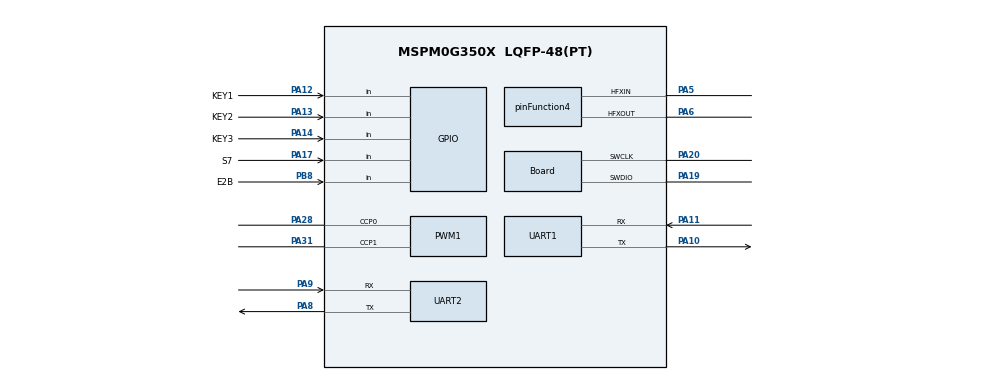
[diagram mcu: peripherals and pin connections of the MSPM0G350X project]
/**
 * @cliArgs --device "MSPM0G350X" --part "Default" --package "LQFP-48(PT)" --product "mspm0_sdk@2.05.01.01"
 * @versions {"tool":"1.24.0+4110"}
 */

/**
 * Import the modules used in this configuration.
 */
const GPIO    = scripting.addModule("/ti/driverlib/GPIO", {}, false);
const GPIO1   = GPIO.addInstance();
const GPIO2   = GPIO.addInstance();
const GPIO3   = GPIO.addInstance();
const GPIO4   = GPIO.addInstance();
const GPIO5   = GPIO.addInstance();
const GPIO6   = GPIO.addInstance();
const PWM     = scripting.addModule("/ti/driverlib/PWM", {}, false);
const PWM1    = PWM.addInstance();
const SYSCTL  = scripting.addModule("/ti/driverlib/SYSCTL");
const SYSTICK = scripting.addModule("/ti/driverlib/SYSTICK");
const TIMER   = scripting.addModule("/ti/driverlib/TIMER", {}, false);
const TIMER1  = TIMER.addInstance();
const TIMER2  = TIMER.addInstance();
const UART    = scripting.addModule("/ti/driverlib/UART", {}, false);
const UART1   = UART.addInstance();
const UART2   = UART.addInstance();

/**
 * Write custom configuration values to the imported modules.
 */
const divider5       = system.clockTree["PLL_CLK1_DIV"];
divider5.divideValue = 4;

const divider6       = system.clockTree["PLL_CLK2X_DIV"];
divider6.divideValue = 4;

const divider9       = system.clockTree["UDIV"];
divider9.divideValue = 2;

const gate7  = system.clockTree["MFCLKGATE"];
gate7.enable = true;

const multiplier2         = system.clockTree["PLL_QDIV"];
multiplier2.multiplyValue = 4;

const mux4       = system.clockTree["EXHFMUX"];
mux4.inputSelect = "EXHFMUX_XTAL";

const mux8       = system.clockTree["HSCLKMUX"];
mux8.inputSelect = "HSCLKMUX_SYSPLL2X";

const mux12       = system.clockTree["SYSPLLMUX"];
mux12.inputSelect = "zSYSPLLMUX_HFCLK";

const pinFunction4                        = system.clockTree["HFXT"];
pinFunction4.inputFreq                    = 40;
pinFunction4.enable                       = true;
pinFunction4.HFXTStartup                  = 10;
pinFunction4.HFCLKMonitor                 = true;
pinFunction4.peripheral.$assign           = "SYSCTL";
pinFunction4.peripheral.hfxInPin.$assign  = "PA5";
pinFunction4.peripheral.hfxOutPin.$assign = "PA6";

GPIO1.port                                  = "PORTA";
GPIO1.$name                                 = "LED";
GPIO1.associatedPins[0].assignedPortSegment = "Lower";
GPIO1.associatedPins[0].assignedPin         = "7";
GPIO1.associatedPins[0].$name               = "LED1";
GPIO1.associatedPins[0].initialValue        = "SET";

const Board                       = scripting.addModule("/ti/driverlib/Board", {}, false);
Board.peripheral.$assign          = "DEBUGSS";
Board.peripheral.swclkPin.$assign = "PA20";
Board.peripheral.swdioPin.$assign = "PA19";

GPIO2.$name                              = "KEY";
GPIO2.associatedPins.create(4);
GPIO2.associatedPins[0].direction        = "INPUT";
GPIO2.associatedPins[0].assignedPort     = "PORTA";
GPIO2.associatedPins[0].interruptEn      = true;
GPIO2.associatedPins[0].polarity         = "RISE";
GPIO2.associatedPins[0].$name            = "KEY1";
GPIO2.associatedPins[0].assignedPin      = "12";
GPIO2.associatedPins[0].internalResistor = "PULL_DOWN";
GPIO2.associatedPins[0].inputFilter      = "8_CYCLES";
GPIO2.associatedPins[0].pin.$assign      = "PA12";
GPIO2.associatedPins[1].$name            = "KEY2";
GPIO2.associatedPins[1].direction        = "INPUT";
GPIO2.associatedPins[1].assignedPort     = "PORTA";
GPIO2.associatedPins[1].assignedPin      = "13";
GPIO2.associatedPins[1].internalResistor = "PULL_DOWN";
GPIO2.associatedPins[1].inputFilter      = "3_CYCLES";
GPIO2.associatedPins[1].pin.$assign      = "PA13";
GPIO2.associatedPins[2].$name            = "KEY3";
GPIO2.associatedPins[2].direction        = "INPUT";
GPIO2.associatedPins[2].assignedPort     = "PORTA";
GPIO2.associatedPins[2].assignedPin      = "14";
GPIO2.associatedPins[2].internalResistor = "PULL_DOWN";
GPIO2.associatedPins[2].inputFilter      = "3_CYCLES";
GPIO2.associatedPins[2].pin.$assign      = "PA14";
GPIO2.associatedPins[3].$name            = "KEY4";
GPIO2.associatedPins[3].direction        = "INPUT";
GPIO2.associatedPins[3].assignedPort     = "PORTA";
GPIO2.associatedPins[3].assignedPin      = "15";
GPIO2.associatedPins[3].internalResistor = "PULL_DOWN";
GPIO2.associatedPins[3].inputFilter      = "3_CYCLES";

GPIO3.$name                               = "ENCODER";
GPIO3.associatedPins.create(4);
GPIO3.associatedPins[0].$name             = "E1A";
GPIO3.associatedPins[0].direction         = "INPUT";
GPIO3.associatedPins[0].assignedPort      = "PORTB";
GPIO3.associatedPins[0].assignedPin       = "18";
GPIO3.associatedPins[0].interruptEn       = true;
GPIO3.associatedPins[0].interruptPriority = "0";
GPIO3.associatedPins[0].polarity          = "RISE";
GPIO3.associatedPins[1].$name             = "E1B";
GPIO3.associatedPins[1].direction         = "INPUT";
GPIO3.associatedPins[1].assignedPort      = "PORTB";
GPIO3.associatedPins[1].assignedPin       = "6";
GPIO3.associatedPins[1].interruptEn       = true;
GPIO3.associatedPins[1].interruptPriority = "0";
GPIO3.associatedPins[1].polarity          = "RISE";
GPIO3.associatedPins[2].$name             = "E2A";
GPIO3.associatedPins[2].direction         = "INPUT";
GPIO3.associatedPins[2].assignedPort      = "PORTB";
GPIO3.associatedPins[2].assignedPin       = "7";
GPIO3.associatedPins[2].interruptEn       = true;
GPIO3.associatedPins[2].interruptPriority = "0";
GPIO3.associatedPins[2].polarity          = "RISE";
GPIO3.associatedPins[3].$name             = "E2B";
GPIO3.associatedPins[3].direction         = "INPUT";
GPIO3.associatedPins[3].assignedPort      = "PORTB";
GPIO3.associatedPins[3].assignedPin       = "8";
GPIO3.associatedPins[3].interruptEn       = true;
GPIO3.associatedPins[3].interruptPriority = "0";
GPIO3.associatedPins[3].polarity          = "RISE";
GPIO3.associatedPins[3].pin.$assign       = "PB8";

GPIO4.$name                          = "MOTOR";
GPIO4.associatedPins.create(4);
GPIO4.associatedPins[0].$name        = "AIN1";
GPIO4.associatedPins[0].assignedPort = "PORTA";
GPIO4.associatedPins[0].assignedPin  = "02";
GPIO4.associatedPins[1].$name        = "AIN2";
GPIO4.associatedPins[1].assignedPort = "PORTB";
GPIO4.associatedPins[1].assignedPin  = "24";
GPIO4.associatedPins[2].$name        = "BIN1";
GPIO4.associatedPins[2].assignedPort = "PORTB";
GPIO4.associatedPins[2].assignedPin  = "20";
GPIO4.associatedPins[3].$name        = "BIN2";
GPIO4.associatedPins[3].assignedPort = "PORTB";
GPIO4.associatedPins[3].assignedPin  = "19";

GPIO5.$name                          = "IIC";
GPIO5.associatedPins.create(2);
GPIO5.associatedPins[0].assignedPort = "PORTA";
GPIO5.associatedPins[0].assignedPin  = "0";
GPIO5.associatedPins[0].$name        = "SCL";
GPIO5.associatedPins[0].initialValue = "SET";
GPIO5.associatedPins[0].ioStructure  = "OD";
GPIO5.associatedPins[1].$name        = "SDA";
GPIO5.associatedPins[1].assignedPort = "PORTA";
GPIO5.associatedPins[1].assignedPin  = "1";
GPIO5.associatedPins[1].initialValue = "SET";
GPIO5.associatedPins[1].ioStructure  = "OD";

GPIO6.$name                          = "TRACK";
GPIO6.associatedPins.create(8);
GPIO6.associatedPins[0].$name        = "S1";
GPIO6.associatedPins[0].direction    = "INPUT";
GPIO6.associatedPins[0].assignedPort = "PORTA";
GPIO6.associatedPins[0].assignedPin  = "25";
GPIO6.associatedPins[1].$name        = "S2";
GPIO6.associatedPins[1].direction    = "INPUT";
GPIO6.associatedPins[1].assignedPort = "PORTA";
GPIO6.associatedPins[1].assignedPin  = "24";
GPIO6.associatedPins[2].$name        = "S3";
GPIO6.associatedPins[2].direction    = "INPUT";
GPIO6.associatedPins[2].assignedPort = "PORTA";
GPIO6.associatedPins[2].assignedPin  = "23";
GPIO6.associatedPins[3].$name        = "S4";
GPIO6.associatedPins[3].direction    = "INPUT";
GPIO6.associatedPins[3].assignedPort = "PORTA";
GPIO6.associatedPins[3].assignedPin  = "22";
GPIO6.associatedPins[4].direction    = "INPUT";
GPIO6.associatedPins[4].$name        = "S5";
GPIO6.associatedPins[4].assignedPort = "PORTA";
GPIO6.associatedPins[4].assignedPin  = "21";
GPIO6.associatedPins[5].$name        = "S6";
GPIO6.associatedPins[5].direction    = "INPUT";
GPIO6.associatedPins[5].assignedPort = "PORTB";
GPIO6.associatedPins[5].assignedPin  = "9";
GPIO6.associatedPins[6].$name        = "S7";
GPIO6.associatedPins[6].direction    = "INPUT";
GPIO6.associatedPins[6].assignedPort = "PORTA";
GPIO6.associatedPins[6].assignedPin  = "17";
GPIO6.associatedPins[6].pin.$assign  = "PA17";
GPIO6.associatedPins[7].$name        = "S8";
GPIO6.associatedPins[7].direction    = "INPUT";
GPIO6.associatedPins[7].assignedPort = "PORTA";
GPIO6.associatedPins[7].assignedPin  = "16";

PWM1.$name                              = "PWM_MOTOR";
PWM1.timerCount                         = 10000;
PWM1.timerStartTimer                    = true;
PWM1.peripheral.$assign                 = "TIMG7";
PWM1.peripheral.ccp0Pin.$assign         = "PA28";
PWM1.peripheral.ccp1Pin.$assign         = "PA31";
PWM1.PWM_CHANNEL_0.$name                = "ti_driverlib_pwm_PWMTimerCC0";
PWM1.PWM_CHANNEL_0.invert               = true;
PWM1.PWM_CHANNEL_1.$name                = "ti_driverlib_pwm_PWMTimerCC1";
PWM1.PWM_CHANNEL_1.invert               = true;
PWM1.ccp0PinConfig.direction            = scripting.forceWrite("OUTPUT");
PWM1.ccp0PinConfig.hideOutputInversion  = scripting.forceWrite(false);
PWM1.ccp0PinConfig.onlyInternalResistor = scripting.forceWrite(false);
PWM1.ccp0PinConfig.passedPeripheralType = scripting.forceWrite("Digital");
PWM1.ccp0PinConfig.$name                = "ti_driverlib_gpio_GPIOPinGeneric2";
PWM1.ccp1PinConfig.direction            = scripting.forceWrite("OUTPUT");
PWM1.ccp1PinConfig.hideOutputInversion  = scripting.forceWrite(false);
PWM1.ccp1PinConfig.onlyInternalResistor = scripting.forceWrite(false);
PWM1.ccp1PinConfig.passedPeripheralType = scripting.forceWrite("Digital");
PWM1.ccp1PinConfig.$name                = "ti_driverlib_gpio_GPIOPinGeneric3";

SYSCTL.forceDefaultClkConfig = true;
SYSCTL.clockTreeEn           = true;
scripting.suppress("For best practices when the CPUCLK is running at 32MHz and above, clear the flash status bit using DL_FlashCTL_executeClearStatus\\(\\) before executing any flash operation\\. Otherwise there may be false positives\\.", SYSCTL);

SYSTICK.periodEnable      = true;
SYSTICK.period            = 80;
SYSTICK.interruptPriority = "3";
SYSTICK.systickEnable     = true;

TIMER1.$name              = "TIMER_0";
TIMER1.timerMode          = "PERIODIC";
TIMER1.timerClkPrescale   = 200;
TIMER1.timerClkSrc        = "MFCLK";
TIMER1.interrupts         = ["ZERO"];
TIMER1.timerStartTimer    = true;
TIMER1.timerPeriod        = "5 ms";
TIMER1.interruptPriority  = "2";
TIMER1.peripheral.$assign = "TIMA0";

TIMER2.$name              = "TIMER_1";
TIMER2.timerMode          = "PERIODIC";
TIMER2.timerStartTimer    = true;
TIMER2.interrupts         = ["ZERO"];
TIMER2.timerClkPrescale   = 100;
TIMER2.interruptPriority  = "1";
TIMER2.timerPeriod        = "10ms";
TIMER2.peripheral.$assign = "TIMA1";

UART1.targetBaudRate                   = 115200;
UART1.$name                            = "UART_DEBUG";
UART1.peripheral.$assign               = "UART0";
UART1.peripheral.rxPin.$assign         = "PA11";
UART1.peripheral.txPin.$assign         = "PA10";
UART1.txPinConfig.direction            = scripting.forceWrite("OUTPUT");
UART1.txPinConfig.hideOutputInversion  = scripting.forceWrite(false);
UART1.txPinConfig.onlyInternalResistor = scripting.forceWrite(false);
UART1.txPinConfig.passedPeripheralType = scripting.forceWrite("Digital");
UART1.txPinConfig.$name                = "ti_driverlib_gpio_GPIOPinGeneric0";
UART1.rxPinConfig.hideOutputInversion  = scripting.forceWrite(false);
UART1.rxPinConfig.onlyInternalResistor = scripting.forceWrite(false);
UART1.rxPinConfig.passedPeripheralType = scripting.forceWrite("Digital");
UART1.rxPinConfig.$name                = "ti_driverlib_gpio_GPIOPinGeneric1";

UART2.targetBaudRate                   = 115200;
UART2.enableFIFO                       = true;
UART2.rxTimeoutValue                   = 1;
UART2.enabledInterrupts                = ["RX_TIMEOUT_ERROR"];
UART2.enabledDMARXTriggers             = "DL_UART_DMA_INTERRUPT_RX";
UART2.interruptPriority                = "1";
UART2.$name                            = "UART_GYRO";
UART2.peripheral.$assign               = "UART1";
UART2.peripheral.rxPin.$assign         = "PA9";
UART2.peripheral.txPin.$assign         = "PA8";
UART2.txPinConfig.$name                = "ti_driverlib_gpio_GPIOPinGeneric4";
UART2.txPinConfig.direction            = scripting.forceWrite("OUTPUT");
UART2.txPinConfig.hideOutputInversion  = scripting.forceWrite(false);
UART2.txPinConfig.onlyInternalResistor = scripting.forceWrite(false);
UART2.txPinConfig.passedPeripheralType = scripting.forceWrite("Digital");
UART2.rxPinConfig.$name                = "ti_driverlib_gpio_GPIOPinGeneric5";
UART2.rxPinConfig.hideOutputInversion  = scripting.forceWrite(false);
UART2.rxPinConfig.onlyInternalResistor = scripting.forceWrite(false);
UART2.rxPinConfig.passedPeripheralType = scripting.forceWrite("Digital");
UART2.DMA_CHANNEL_RX.$name             = "DMA_GYRO";
UART2.DMA_CHANNEL_RX.addressMode       = "f2b";
UART2.DMA_CHANNEL_RX.srcLength         = "BYTE";
UART2.DMA_CHANNEL_RX.dstLength         = "BYTE";

const ProjectConfig              = scripting.addModule("/ti/project_config/ProjectConfig", {}, false);
ProjectConfig.migrationCondition = true;

/**
 * Pinmux solution for unlocked pins/peripherals. This ensures that minor changes to the automatic solver in a future
 * version of the tool will not impact the pinmux you originally saw.  These lines can be completely deleted in order to
 * re-solve from scratch.
 */
GPIO1.associatedPins[0].pin.$suggestSolution     = "PA7";
GPIO2.associatedPins[3].pin.$suggestSolution     = "PA15";
GPIO3.associatedPins[0].pin.$suggestSolution     = "PB18";
GPIO3.associatedPins[1].pin.$suggestSolution     = "PB6";
GPIO3.associatedPins[2].pin.$suggestSolution     = "PB7";
GPIO4.associatedPins[0].pin.$suggestSolution     = "PA2";
GPIO4.associatedPins[1].pin.$suggestSolution     = "PB24";
GPIO4.associatedPins[2].pin.$suggestSolution     = "PB20";
GPIO4.associatedPins[3].pin.$suggestSolution     = "PB19";
GPIO5.associatedPins[0].pin.$suggestSolution     = "PA0";
GPIO5.associatedPins[1].pin.$suggestSolution     = "PA1";
GPIO6.associatedPins[0].pin.$suggestSolution     = "PA25";
GPIO6.associatedPins[1].pin.$suggestSolution     = "PA24";
GPIO6.associatedPins[2].pin.$suggestSolution     = "PA23";
GPIO6.associatedPins[3].pin.$suggestSolution     = "PA22";
GPIO6.associatedPins[4].pin.$suggestSolution     = "PA21";
GPIO6.associatedPins[5].pin.$suggestSolution     = "PB9";
GPIO6.associatedPins[7].pin.$suggestSolution     = "PA16";
UART2.DMA_CHANNEL_RX.peripheral.$suggestSolution = "DMA_CH0";
